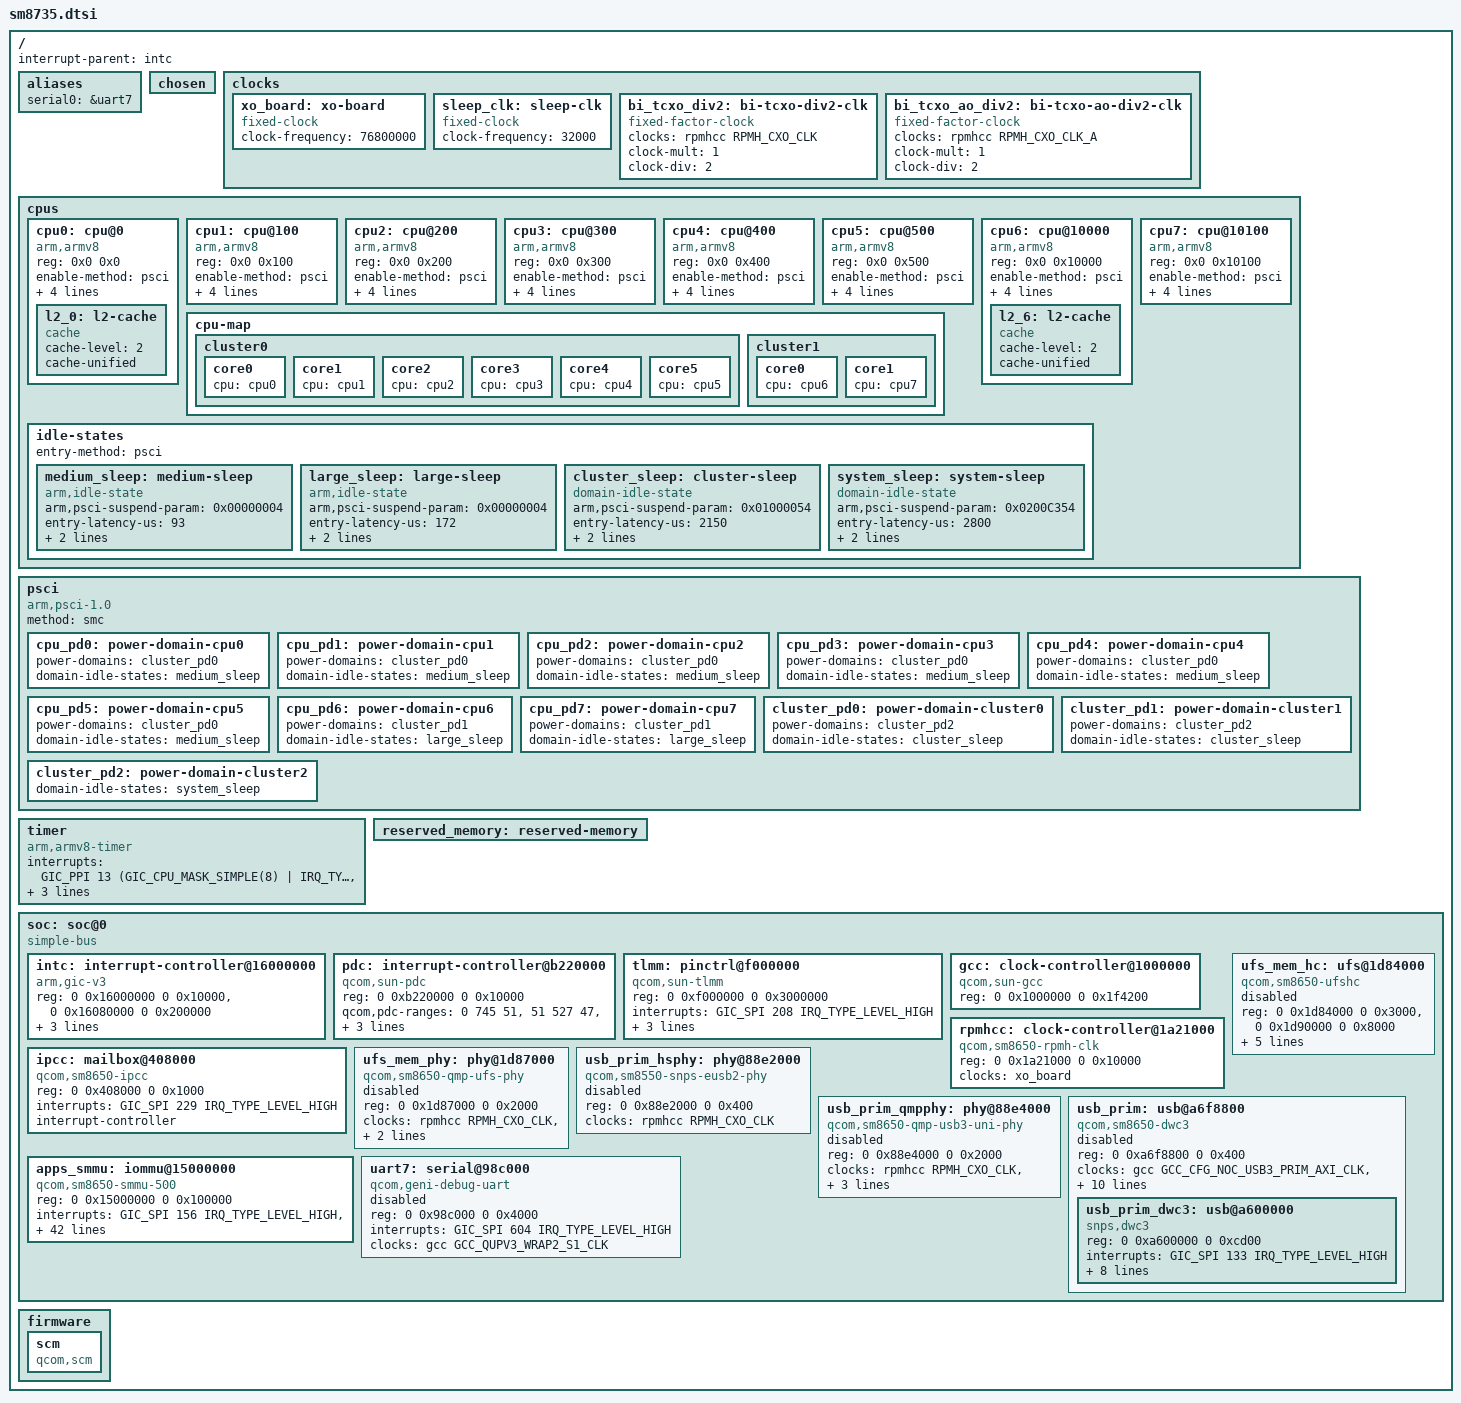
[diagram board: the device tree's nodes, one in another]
// SPDX-License-Identifier: BSD-3-Clause OR GPL-2.0
/*
 * Device Tree Source for Qualcomm SM8735 (Snapdragon 8s Gen 4 / "Sun") SoC
 *
 * Based on Android kernel vendor DTS (sun.dtsi) and upstream Qualcomm DTS patterns.
 *
 * TARGET KERNEL: Linux 7.1.1 (2026-06-19)
 *
 * STATUS: SM8735 (qcom,sun-*) 驱动尚未合入主线内核。
 *         兼容字符串保留为未来上游驱动预留。
 *         当前编译目标：Linux 7.1.1，通过 GitHub Actions 云端编译。
 *
 * KNOWN ISSUES:
 * - qcom,sun-gcc: 无主线驱动匹配，需要从 ACK 6.6 移植
 * - qcom,sun-tlmm: 无主线驱动匹配，需要从 ACK 6.6 移植
 * - qcom,sun-pdc: fallback qcom,pdc 在主线中存在
 *
 * This is a WORK IN PROGRESS - not all peripherals are defined yet.
 *
 * Sun clock binding headers are fetched from OnePlusOSS ACK 6.6.89
 * by the CI workflow. If building locally, download from:
 *   https://github.com/OnePlusOSS/android_kernel_oneplus_sm8735
 *   branch: oneplus/sm8735_b_16.0.0_turbo_6
 */
 
#include <dt-bindings/clock/qcom,gcc-sun.h>
#include <dt-bindings/clock/qcom,rpmh.h>
#include <dt-bindings/interrupt-controller/arm-gic.h>
#include <dt-bindings/mailbox/qcom-ipcc.h>
#include <dt-bindings/power/qcom-rpmpd.h>
#include <dt-bindings/power/qcom,rpmhpd.h>
#include <dt-bindings/soc/qcom,rpmh-rsc.h>
#include <dt-bindings/thermal/thermal.h>

/ {
	interrupt-parent = <&intc>;

	#address-cells = <2>;
	#size-cells = <2>;

	aliases {
		serial0 = &uart7;
	};

	chosen { };

	clocks {
		xo_board: xo-board {
			compatible = "fixed-clock";
			#clock-cells = <0>;
			clock-frequency = <76800000>;
		};

		sleep_clk: sleep-clk {
			compatible = "fixed-clock";
			#clock-cells = <0>;
			clock-frequency = <32000>;
		};

		bi_tcxo_div2: bi-tcxo-div2-clk {
			compatible = "fixed-factor-clock";
			#clock-cells = <0>;
			clocks = <&rpmhcc RPMH_CXO_CLK>;
			clock-mult = <1>;
			clock-div = <2>;
		};

		bi_tcxo_ao_div2: bi-tcxo-ao-div2-clk {
			compatible = "fixed-factor-clock";
			#clock-cells = <0>;
			clocks = <&rpmhcc RPMH_CXO_CLK_A>;
			clock-mult = <1>;
			clock-div = <2>;
		};
	};

	cpus {
		#address-cells = <2>;
		#size-cells = <0>;

		cpu0: cpu@0 {
			device_type = "cpu";
			compatible = "arm,armv8";
			reg = <0x0 0x0>;
			enable-method = "psci";
			capacity-dmips-mhz = <1792>;
			dynamic-power-coefficient = <238>;
			next-level-cache = <&l2_0>;
			power-domains = <&cpu_pd0>;
			power-domain-names = "psci";
			#cooling-cells = <2>;
			l2_0: l2-cache {
				compatible = "cache";
				cache-level = <2>;
				cache-unified;
			};
		};

		cpu1: cpu@100 {
			device_type = "cpu";
			compatible = "arm,armv8";
			reg = <0x0 0x100>;
			enable-method = "psci";
			capacity-dmips-mhz = <1792>;
			dynamic-power-coefficient = <238>;
			next-level-cache = <&l2_0>;
			power-domains = <&cpu_pd1>;
			power-domain-names = "psci";
			#cooling-cells = <2>;
		};

		cpu2: cpu@200 {
			device_type = "cpu";
			compatible = "arm,armv8";
			reg = <0x0 0x200>;
			enable-method = "psci";
			capacity-dmips-mhz = <1792>;
			dynamic-power-coefficient = <238>;
			next-level-cache = <&l2_0>;
			power-domains = <&cpu_pd2>;
			power-domain-names = "psci";
			#cooling-cells = <2>;
		};

		cpu3: cpu@300 {
			device_type = "cpu";
			compatible = "arm,armv8";
			reg = <0x0 0x300>;
			enable-method = "psci";
			capacity-dmips-mhz = <1792>;
			dynamic-power-coefficient = <238>;
			next-level-cache = <&l2_0>;
			power-domains = <&cpu_pd3>;
			power-domain-names = "psci";
			#cooling-cells = <2>;
		};

		cpu4: cpu@400 {
			device_type = "cpu";
			compatible = "arm,armv8";
			reg = <0x0 0x400>;
			enable-method = "psci";
			capacity-dmips-mhz = <1792>;
			dynamic-power-coefficient = <238>;
			next-level-cache = <&l2_0>;
			power-domains = <&cpu_pd4>;
			power-domain-names = "psci";
			#cooling-cells = <2>;
		};

		cpu5: cpu@500 {
			device_type = "cpu";
			compatible = "arm,armv8";
			reg = <0x0 0x500>;
			enable-method = "psci";
			capacity-dmips-mhz = <1792>;
			dynamic-power-coefficient = <238>;
			next-level-cache = <&l2_0>;
			power-domains = <&cpu_pd5>;
			power-domain-names = "psci";
			#cooling-cells = <2>;
		};

		cpu6: cpu@10000 {
			device_type = "cpu";
			compatible = "arm,armv8";
			reg = <0x0 0x10000>;
			enable-method = "psci";
			capacity-dmips-mhz = <1894>;
			dynamic-power-coefficient = <588>;
			next-level-cache = <&l2_6>;
			power-domains = <&cpu_pd6>;
			power-domain-names = "psci";
			#cooling-cells = <2>;
			l2_6: l2-cache {
				compatible = "cache";
				cache-level = <2>;
				cache-unified;
			};
		};

		cpu7: cpu@10100 {
			device_type = "cpu";
			compatible = "arm,armv8";
			reg = <0x0 0x10100>;
			enable-method = "psci";
			capacity-dmips-mhz = <1894>;
			dynamic-power-coefficient = <588>;
			next-level-cache = <&l2_6>;
			power-domains = <&cpu_pd7>;
			power-domain-names = "psci";
			#cooling-cells = <2>;
		};

		cpu-map {
			cluster0 {
				core0 { cpu = <&cpu0>; };
				core1 { cpu = <&cpu1>; };
				core2 { cpu = <&cpu2>; };
				core3 { cpu = <&cpu3>; };
				core4 { cpu = <&cpu4>; };
				core5 { cpu = <&cpu5>; };
			};

			cluster1 {
				core0 { cpu = <&cpu6>; };
				core1 { cpu = <&cpu7>; };
			};
		};

		idle-states {
			entry-method = "psci";

			medium_sleep: medium-sleep {
				compatible = "arm,idle-state";
				arm,psci-suspend-param = <0x00000004>;
				entry-latency-us = <93>;
				exit-latency-us = <129>;
				min-residency-us = <560>;
			};

			large_sleep: large-sleep {
				compatible = "arm,idle-state";
				arm,psci-suspend-param = <0x00000004>;
				entry-latency-us = <172>;
				exit-latency-us = <130>;
				min-residency-us = <686>;
			};

			cluster_sleep: cluster-sleep {
				compatible = "domain-idle-state";
				arm,psci-suspend-param = <0x01000054>;
				entry-latency-us = <2150>;
				exit-latency-us = <1983>;
				min-residency-us = <9144>;
			};

			system_sleep: system-sleep {
				compatible = "domain-idle-state";
				arm,psci-suspend-param = <0x0200C354>;
				entry-latency-us = <2800>;
				exit-latency-us = <4400>;
				min-residency-us = <10150>;
			};
		};
	};

	psci {
		compatible = "arm,psci-1.0";
		method = "smc";

		cpu_pd0: power-domain-cpu0 {
			#power-domain-cells = <0>;
			power-domains = <&cluster_pd0>;
			domain-idle-states = <&medium_sleep>;
		};

		cpu_pd1: power-domain-cpu1 {
			#power-domain-cells = <0>;
			power-domains = <&cluster_pd0>;
			domain-idle-states = <&medium_sleep>;
		};

		cpu_pd2: power-domain-cpu2 {
			#power-domain-cells = <0>;
			power-domains = <&cluster_pd0>;
			domain-idle-states = <&medium_sleep>;
		};

		cpu_pd3: power-domain-cpu3 {
			#power-domain-cells = <0>;
			power-domains = <&cluster_pd0>;
			domain-idle-states = <&medium_sleep>;
		};

		cpu_pd4: power-domain-cpu4 {
			#power-domain-cells = <0>;
			power-domains = <&cluster_pd0>;
			domain-idle-states = <&medium_sleep>;
		};

		cpu_pd5: power-domain-cpu5 {
			#power-domain-cells = <0>;
			power-domains = <&cluster_pd0>;
			domain-idle-states = <&medium_sleep>;
		};

		cpu_pd6: power-domain-cpu6 {
			#power-domain-cells = <0>;
			power-domains = <&cluster_pd1>;
			domain-idle-states = <&large_sleep>;
		};

		cpu_pd7: power-domain-cpu7 {
			#power-domain-cells = <0>;
			power-domains = <&cluster_pd1>;
			domain-idle-states = <&large_sleep>;
		};

		cluster_pd0: power-domain-cluster0 {
			#power-domain-cells = <0>;
			power-domains = <&cluster_pd2>;
			domain-idle-states = <&cluster_sleep>;
		};

		cluster_pd1: power-domain-cluster1 {
			#power-domain-cells = <0>;
			power-domains = <&cluster_pd2>;
			domain-idle-states = <&cluster_sleep>;
		};

		cluster_pd2: power-domain-cluster2 {
			#power-domain-cells = <0>;
			domain-idle-states = <&system_sleep>;
		};
	};

	timer {
		compatible = "arm,armv8-timer";
		interrupts = <GIC_PPI 13 (GIC_CPU_MASK_SIMPLE(8) | IRQ_TYPE_LEVEL_LOW)>,
			     <GIC_PPI 14 (GIC_CPU_MASK_SIMPLE(8) | IRQ_TYPE_LEVEL_LOW)>,
			     <GIC_PPI 11 (GIC_CPU_MASK_SIMPLE(8) | IRQ_TYPE_LEVEL_LOW)>,
			     <GIC_PPI 10 (GIC_CPU_MASK_SIMPLE(8) | IRQ_TYPE_LEVEL_LOW)>;
	};

	reserved_memory: reserved-memory { };

	soc: soc@0 {
		compatible = "simple-bus";
		#address-cells = <2>;
		#size-cells = <2>;
		ranges = <0 0 0 0 0xffffffff>;

		intc: interrupt-controller@16000000 {
			compatible = "arm,gic-v3";
			reg = <0 0x16000000 0 0x10000>,     /* GICD */
			      <0 0x16080000 0 0x200000>;    /* GICR * 8 */
			interrupts = <GIC_PPI 9 IRQ_TYPE_LEVEL_LOW>;
			interrupt-controller;
			#interrupt-cells = <3>;
			#redistributor-regions = <1>;
		};

		pdc: interrupt-controller@b220000 {
			compatible = "qcom,sun-pdc", "qcom,pdc";
			reg = <0 0xb220000 0 0x10000>;
			qcom,pdc-ranges = <0 745 51>, <51 527 47>,
					  <98 609 32>, <130 717 12>,
					  <142 251 5>, <147 796 16>;
			#interrupt-cells = <2>;
			interrupt-parent = <&intc>;
			interrupt-controller;
		};

		tlmm: pinctrl@f000000 {
			compatible = "qcom,sun-tlmm", "qcom,tlmm";
			reg = <0 0xf000000 0 0x3000000>;
			interrupts = <GIC_SPI 208 IRQ_TYPE_LEVEL_HIGH>;
			gpio-controller;
			#gpio-cells = <2>;
			gpio-ranges = <&tlmm 0 0 200>;
			interrupt-controller;
			#interrupt-cells = <2>;
		};

		gcc: clock-controller@1000000 {
			compatible = "qcom,sun-gcc";
			reg = <0 0x1000000 0 0x1f4200>;
			#clock-cells = <1>;
			#reset-cells = <1>;
			#power-domain-cells = <1>;
		};

		rpmhcc: clock-controller@1a21000 {
			compatible = "qcom,sm8650-rpmh-clk";
			reg = <0 0x1a21000 0 0x10000>;
			#clock-cells = <1>;
			clock-names = "xo";
			clocks = <&xo_board>;
		};

		ipcc: mailbox@408000 {
			compatible = "qcom,sm8650-ipcc";
			reg = <0 0x408000 0 0x1000>;
			interrupts = <GIC_SPI 229 IRQ_TYPE_LEVEL_HIGH>;
			interrupt-controller;
			#interrupt-cells = <2>;
			#mbox-cells = <2>;
		};

		ufs_mem_hc: ufs@1d84000 {
			compatible = "qcom,sm8650-ufshc", "qcom,ufshc",
				     "jedec,ufs-2.0";
			reg = <0 0x1d84000 0 0x3000>,
			      <0 0x1d90000 0 0x8000>;
			reg-names = "std", "tcq";
			interrupts = <GIC_SPI 265 IRQ_TYPE_LEVEL_HIGH>;
			phys = <&ufs_mem_phy>;
			phy-names = "ufsphy";
			lanes-per-direction = <2>;
			#reset-cells = <1>;
			power-domains = <&gcc GCC_UFS_MEM_PHY_GDSC>;
			iommus = <&apps_smmu 0x1a0 0x0>;
			status = "disabled";
		};

		ufs_mem_phy: phy@1d87000 {
			compatible = "qcom,sm8650-qmp-ufs-phy";
			reg = <0 0x1d87000 0 0x2000>;
			clock-names = "ref", "ref_aux";
			clocks = <&rpmhcc RPMH_CXO_CLK>,
				 <&gcc GCC_UFS_PHY_PHY_AUX_CLK>;
			resets = <&ufs_mem_hc 0>;
			#phy-cells = <0>;
			status = "disabled";
		};

		usb_prim_hsphy: phy@88e2000 {
			compatible = "qcom,sm8550-snps-eusb2-phy";
			reg = <0 0x88e2000 0 0x400>;
			clocks = <&rpmhcc RPMH_CXO_CLK>;
			clock-names = "ref";
			#phy-cells = <0>;
			status = "disabled";
		};

		usb_prim_qmpphy: phy@88e4000 {
			compatible = "qcom,sm8650-qmp-usb3-uni-phy";
			reg = <0 0x88e4000 0 0x2000>;
			clock-names = "ref", "ref_aux";
			clocks = <&rpmhcc RPMH_CXO_CLK>,
				 <&gcc GCC_USB3_PRIM_PHY_PIPE_CLK>;
			power-domains = <&gcc GCC_USB3_PHY_GDSC>;
			resets = <&gcc GCC_USB3_PHY_PRIM_BCR>;
			#phy-cells = <0>;
			status = "disabled";
		};

		usb_prim: usb@a6f8800 {
			compatible = "qcom,sm8650-dwc3", "qcom,dwc3";
			reg = <0 0xa6f8800 0 0x400>;
			clocks = <&gcc GCC_CFG_NOC_USB3_PRIM_AXI_CLK>,
				 <&gcc GCC_USB30_PRIM_MASTER_CLK>,
				 <&gcc GCC_AGGRE_USB3_PRIM_AXI_CLK>,
				 <&gcc GCC_USB30_PRIM_MOCK_UTMI_CLK>,
				 <&gcc GCC_USB30_PRIM_SLEEP_CLK>;
			clock-names = "cfg_noc", "core", "iface",
				      "mock_utmi", "sleep";
			interrupts-extended = <&pdc 13 IRQ_TYPE_EDGE_RISING>,
					      <&pdc 12 IRQ_TYPE_EDGE_RISING>,
					      <&pdc 14 IRQ_TYPE_LEVEL_HIGH>;
			interrupt-names = "dp_hs_phy_irq", "dm_hs_phy_irq",
					  "ss_phy_irq";
			power-domains = <&gcc GCC_USB30_PRIM_GDSC>;
			resets = <&gcc GCC_USB30_PRIM_BCR>;
			#address-cells = <2>;
			#size-cells = <2>;
			ranges;
			status = "disabled";

			usb_prim_dwc3: usb@a600000 {
				compatible = "snps,dwc3";
				reg = <0 0xa600000 0 0xcd00>;
				interrupts = <GIC_SPI 133 IRQ_TYPE_LEVEL_HIGH>;
				iommus = <&apps_smmu 0x0 0x0>;
				phys = <&usb_prim_hsphy>,
				       <&usb_prim_qmpphy>;
				phy-names = "usb2-phy", "usb3-phy";
				snps,dis-u1-entry-quirk;
				snps,dis-u2-entry-quirk;
				snps,dis_u2_susphy_quirk;
				snps,has-lpm-erratum;
				dr_mode = "peripheral";
				maximum-speed = "super-speed-plus";
			};
		};

		apps_smmu: iommu@15000000 {
			compatible = "qcom,sm8650-smmu-500", "arm,mmu-500";
			reg = <0 0x15000000 0 0x100000>;
			interrupts = <GIC_SPI 156 IRQ_TYPE_LEVEL_HIGH>,
				     <GIC_SPI 158 IRQ_TYPE_LEVEL_HIGH>,
				     <GIC_SPI 159 IRQ_TYPE_LEVEL_HIGH>,
				     <GIC_SPI 160 IRQ_TYPE_LEVEL_HIGH>,
				     <GIC_SPI 161 IRQ_TYPE_LEVEL_HIGH>,
				     <GIC_SPI 162 IRQ_TYPE_LEVEL_HIGH>,
				     <GIC_SPI 163 IRQ_TYPE_LEVEL_HIGH>,
				     <GIC_SPI 164 IRQ_TYPE_LEVEL_HIGH>,
				     <GIC_SPI 165 IRQ_TYPE_LEVEL_HIGH>,
				     <GIC_SPI 166 IRQ_TYPE_LEVEL_HIGH>,
				     <GIC_SPI 167 IRQ_TYPE_LEVEL_HIGH>,
				     <GIC_SPI 168 IRQ_TYPE_LEVEL_HIGH>,
				     <GIC_SPI 169 IRQ_TYPE_LEVEL_HIGH>,
				     <GIC_SPI 170 IRQ_TYPE_LEVEL_HIGH>,
				     <GIC_SPI 171 IRQ_TYPE_LEVEL_HIGH>,
				     <GIC_SPI 172 IRQ_TYPE_LEVEL_HIGH>,
				     <GIC_SPI 173 IRQ_TYPE_LEVEL_HIGH>,
				     <GIC_SPI 174 IRQ_TYPE_LEVEL_HIGH>,
				     <GIC_SPI 175 IRQ_TYPE_LEVEL_HIGH>,
				     <GIC_SPI 176 IRQ_TYPE_LEVEL_HIGH>,
				     <GIC_SPI 177 IRQ_TYPE_LEVEL_HIGH>,
				     <GIC_SPI 178 IRQ_TYPE_LEVEL_HIGH>,
				     <GIC_SPI 179 IRQ_TYPE_LEVEL_HIGH>,
				     <GIC_SPI 180 IRQ_TYPE_LEVEL_HIGH>,
				     <GIC_SPI 181 IRQ_TYPE_LEVEL_HIGH>,
				     <GIC_SPI 182 IRQ_TYPE_LEVEL_HIGH>,
				     <GIC_SPI 183 IRQ_TYPE_LEVEL_HIGH>,
				     <GIC_SPI 184 IRQ_TYPE_LEVEL_HIGH>,
				     <GIC_SPI 185 IRQ_TYPE_LEVEL_HIGH>,
				     <GIC_SPI 186 IRQ_TYPE_LEVEL_HIGH>,
				     <GIC_SPI 187 IRQ_TYPE_LEVEL_HIGH>,
				     <GIC_SPI 188 IRQ_TYPE_LEVEL_HIGH>,
				     <GIC_SPI 189 IRQ_TYPE_LEVEL_HIGH>,
				     <GIC_SPI 190 IRQ_TYPE_LEVEL_HIGH>,
				     <GIC_SPI 191 IRQ_TYPE_LEVEL_HIGH>,
				     <GIC_SPI 192 IRQ_TYPE_LEVEL_HIGH>,
				     <GIC_SPI 193 IRQ_TYPE_LEVEL_HIGH>,
				     <GIC_SPI 194 IRQ_TYPE_LEVEL_HIGH>,
				     <GIC_SPI 195 IRQ_TYPE_LEVEL_HIGH>,
				     <GIC_SPI 196 IRQ_TYPE_LEVEL_HIGH>,
				     <GIC_SPI 197 IRQ_TYPE_LEVEL_HIGH>;
			#global-interrupts = <1>;
			dma-coherent;
			#iommu-cells = <1>;
		};

		uart7: serial@98c000 {
			compatible = "qcom,geni-debug-uart";
			reg = <0 0x98c000 0 0x4000>;
			interrupts = <GIC_SPI 604 IRQ_TYPE_LEVEL_HIGH>;
			clocks = <&gcc GCC_QUPV3_WRAP2_S1_CLK>;
			clock-names = "se";
			status = "disabled";
		};
	};

	firmware {
		scm {
			compatible = "qcom,scm";
		};
	};
};
